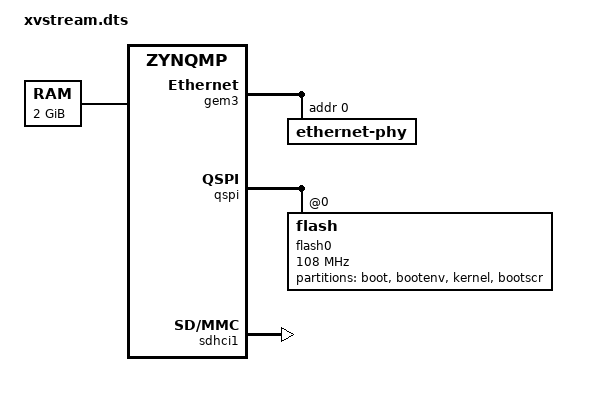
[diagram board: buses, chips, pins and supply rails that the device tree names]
/*
 * CAUTION: This file is automatically generated by Xilinx.
 * Version: XSCT 2020.1
 * Today is: Mon Jan 10 18:49:25 2022
 */


/dts-v1/;
#include "zynqmp.dtsi"
#include "zynqmp-clk-ccf.dtsi"
#include "pl.dtsi"
#include "pcw.dtsi"
/ {
	chosen {
		bootargs = " earlycon console=ttyPS0,115200 clk_ignore_unused root=/dev/mmcblk1p2 rootwait rw";
		stdout-path = "serial0:115200n8";
	};
	aliases {
		ethernet0 = &gem3;
		// i2c0 = &mpsoc_axi_iic_0;
		serial0 = &uart0;
		// serial1 = &uart1;
		spi0 = &qspi;
	};
	memory {
		device_type = "memory";
		reg = <0x0 0x0 0x0 0x7ff00000>;
	};
};

&gem3 {
	local-mac-address = [00 0a 35 00 01 02];
    ethernet-phy@0 {
        reg = <0>;
    };
};

&qspi {
	#address-cells = <1>;
	#size-cells = <0>;
	flash0: flash@0 {
		spi-max-frequency = <108000000>;
		partition@0 {
			label = "boot";
			reg = <0x00000000 0x00a00000>;
		};
		partition@1 {
			label = "bootenv";
			reg = <0x00a00000 0x00010000>;
		};
		partition@2 {
			label = "kernel";
			reg = <0x00a10000 0x01500000>;
		};
		partition@3 {
			label = "bootscr";
			reg = <0x01f10000 0x00010000>;
		};
	};
};

/ {
    reserved-memory {
        #address-cells = <2>;
        #size-cells = <2>;
        ranges;
        rpu0vdev0vring0: rpu0vdev0vring0@3ed40000 {
            no-map;
            reg = <0x0 0x3ed40000 0x0 0x4000>;
        };
        rpu0vdev0vring1: rpu0vdev0vring1@3ed44000 {
            no-map;
            reg = <0x0 0x3ed44000 0x0 0x4000>;
        };
        rpu0vdev0buffer: rpu0vdev0buffer@3ed48000 {
            no-map;
            reg = <0x0 0x3ed48000 0x0 0x100000>;
        };
        rproc_0_reserved: rproc@40000000 {
            no-map;
            reg = <0x0 0x40000000 0x0 0x10000000>;
        };
        /*
        plproc_reserved: plproc@70000000 {
            no-map;
            reg = <0x0 0x70000000 0x0 0x10000000>;
        };
        */
    };

    zynqmp-rpu {
        compatible = "xlnx,zynqmp-r5-remoteproc-1.0";
        #address-cells = <2>;
        #size-cells = <2>;
        ranges;
        core_conf = "split";
        reg = <0x0 0xFF9A0000 0x0 0x10000>;
        r5_0: r5@0 {
            #address-cells = <2>;
            #size-cells = <2>;
            ranges;
            memory-region = <&rproc_0_reserved>, <&rpu0vdev0buffer>, <&rpu0vdev0vring0>, <&rpu0vdev0vring1>;
            pnode-id = <0x7>;
            mboxes = <&ipi_mailbox_rpu0 0>, <&ipi_mailbox_rpu0 1>;
            mbox-names = "tx", "rx";
            tcm_0_a: tcm_0@0 {
                reg = <0x0 0xFFE00000 0x0 0x10000>;
                pnode-id = <0xf>;
            };
            tcm_0_b: tcm_0@1 {
                reg = <0x0 0xFFE20000 0x0 0x10000>;
                pnode-id = <0x10>;
            };
        };
        /* if instead for RPU1 use the following:
        r5_1: r5@1 {
            #address-cells = <2>;
            #size-cells = <2>;
            ranges;
            memory-region = <&rproc_0_fw_reserved>,
                <&rproc_0_dma_reserved>;
            pnode-id = <0x8>;
            mboxes = <&ipi_mailbox_rpu0 0>, <&ipi_mailbox_rpu0 1>;
            mbox-names = "tx", "rx";
            tcm_a: tcm@0 {
                reg = <0x0 0xFFE90000 0x0 0x10000>;
                pnode-id = <0x11>;
            };
            tcm_b: tcm@1 {
                reg = <0x0 0xFFEb0000 0x0 0x10000>;
                pnode-id = <0x12>;
            };
        };
        */
    };


    zynqmp_ipi1 {
        compatible = "xlnx,zynqmp-ipi-mailbox";
        interrupt-parent = <&gic>;
        interrupts = <0 29 4>;
        xlnx,ipi-id = <7>;
        #address-cells = <1>;
        #size-cells = <1>;
        ranges;

        /* APU<->RPU0 IPI mailbox controller */
        ipi_mailbox_rpu0: mailbox@ff990600 {
            reg = <0xff990600 0x20>,
                  <0xff990620 0x20>,
                  <0xff9900c0 0x20>,
                  <0xff9900e0 0x20>;
            reg-names = "local_request_region",
                    "local_response_region",
                    "remote_request_region",
                    "remote_response_region";
            #mbox-cells = <1>;
            xlnx,ipi-id = <1>;
        };
    };
};


&sdhci1 {
	status = "okay";
	no-1-8-v;
};

&uart1 {
	status = "disabled";
};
